AUTOSAR XML (schema 4-2-2)
package /Components
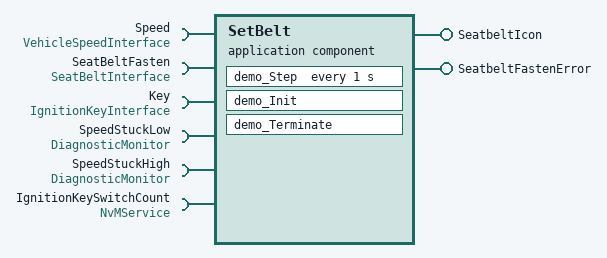
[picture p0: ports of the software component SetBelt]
  application sw component type SetBelt
    require port Speed: nonqueued-receiver-com-spec{data-element=Speed, init-value=0}, required-interface=VehicleSpeedInterface
    require port SeatBeltFasten: nonqueued-receiver-com-spec{data-element=SeatBeltFasten, init-value=0}, required-interface=SeatBeltInterface
    require port Key: nonqueued-receiver-com-spec{data-element=Key, init-value=OFF}, required-interface=IgnitionKeyInterface
    provide port SeatbeltIcon: nonqueued-sender-com-spec{data-element=SeatbeltIcon, init-value=0}, provided-interface=SeatbeltIcon
    provide port SeatbeltFastenError: nonqueued-sender-com-spec{data-element=SeatbeltFastenError, init-value=0}, provided-interface=SeatbeltFastenError
    require port SpeedStuckLow: required-interface=DiagnosticMonitor
    require port SpeedStuckHigh: required-interface=DiagnosticMonitor
    require port IgnitionKeySwitchCount: required-interface=NvMService
    behavior demo_IB: handle-termination-and-restart=NO-SUPPORT
      timing event Event_demo_Step: start-on-event=demo_Step, period=1
      runnable demo_Init
        async call SC_IgnitionKeySwitchCount_ReadBlock: operation=IgnitionKeySwitchCount.ReadBlock, timeout=1
      runnable demo_Step
        data-read-access:
          access IN_Key_Key: accessed-variable=Key.Key
          access IN_SeatBeltFasten_SeatBeltFasten: accessed-variable=SeatBeltFasten.SeatBeltFasten
          access IN_Speed_Speed: accessed-variable=Speed.Speed
        data-write-access:
          access OUT_SeatbeltIcon_SeatbeltIcon: accessed-variable=SeatbeltIcon.SeatbeltIcon
          access OUT_SeatbeltFastenError_SeatbeltFastenError: accessed-variable=SeatbeltFastenError.SeatbeltFastenError
        sync call SC_SpeedStuckHigh_SetEventStatus: operation=SpeedStuckHigh.SetEventStatus, timeout=1.0E-06
        sync call SC_SpeedStuckLow_SetEventStatus: operation=SpeedStuckLow.SetEventStatus, timeout=1.0E-06
        async call SC_IgnitionKeySwitchCount_WriteBlock: operation=IgnitionKeySwitchCount.WriteBlock, timeout=1
      runnable demo_Terminate
        async call SC_IgnitionKeySwitchCount_WriteBlock: operation=IgnitionKeySwitchCount.WriteBlock, timeout=1
